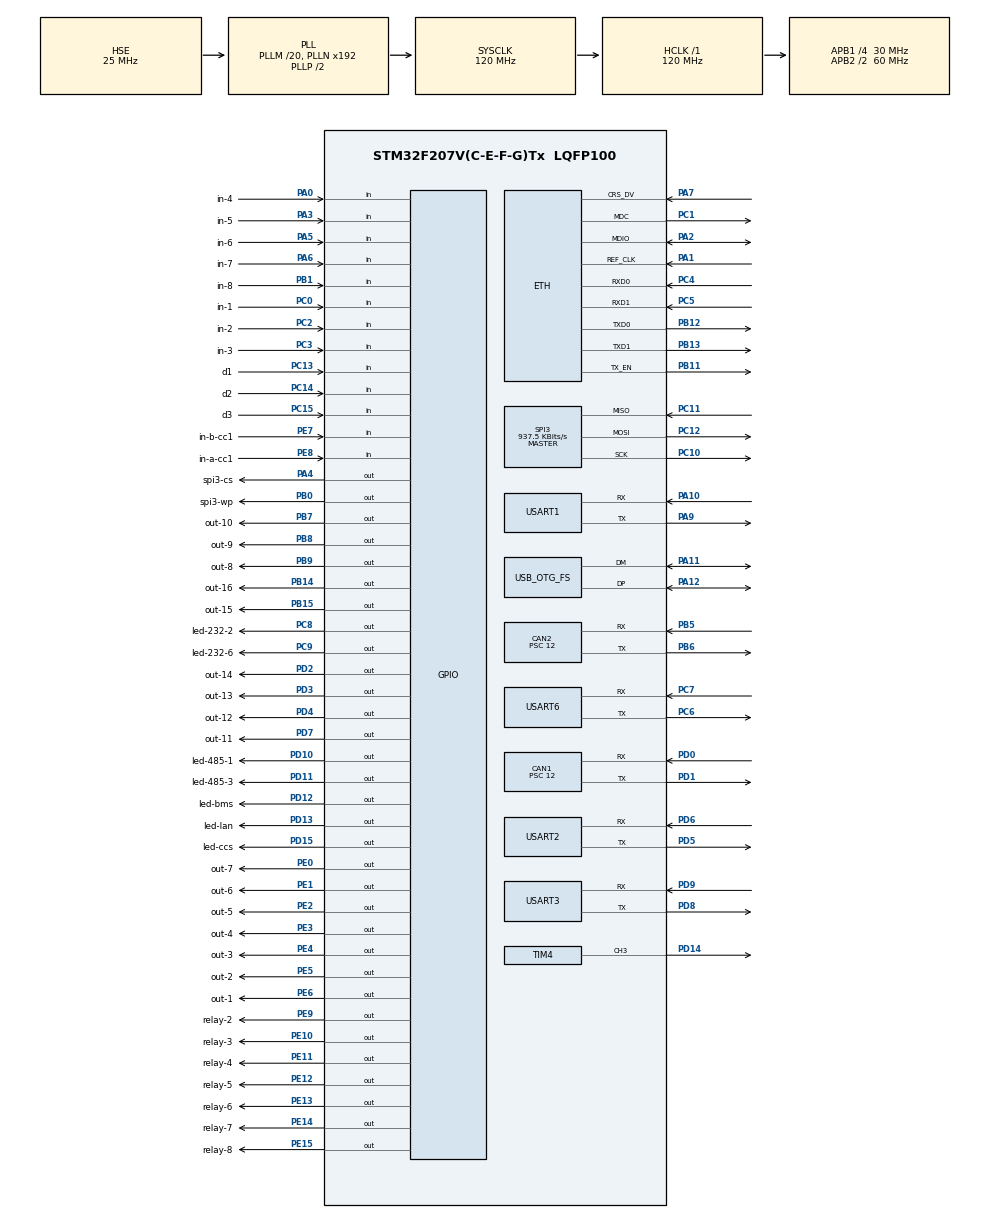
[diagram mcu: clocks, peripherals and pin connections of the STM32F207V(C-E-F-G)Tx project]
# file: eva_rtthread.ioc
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CAN1.ABOM=ENABLE
CAN1.AWUM=DISABLE
CAN1.BS1=CAN_BS1_3TQ
CAN1.BS2=CAN_BS2_6TQ
CAN1.CalculateTimeQuantum=400.0
CAN1.Mode=CAN_MODE_NORMAL
CAN1.NART=ENABLE
CAN1.Prescaler=12
CAN2.ABOM=ENABLE
CAN2.AWUM=DISABLE
CAN2.BS1=CAN_BS1_3TQ
CAN2.BS2=CAN_BS2_6TQ
CAN2.CalculateTimeQuantum=400.0
CAN2.Mode=CAN_MODE_NORMAL
CAN2.NART=ENABLE
CAN2.Prescaler=12
Dma.Request0=USART1_RX
Dma.Request1=USART1_TX
Dma.Request2=USART3_RX
Dma.Request3=USART3_TX
Dma.Request4=USART2_RX
Dma.Request5=USART2_TX
Dma.Request6=USART6_RX
Dma.Request7=USART6_TX
Dma.USART1_RX.0.Direction=DMA_PERIPH_TO_MEMORY
Dma.USART1_RX.0.FIFOMode=DMA_FIFOMODE_DISABLE
Dma.USART1_RX.0.Instance=DMA2_Stream2
Dma.USART1_RX.0.MemDataAlignment=DMA_MDATAALIGN_BYTE
Dma.USART1_RX.0.MemInc=DMA_MINC_ENABLE
Dma.USART1_RX.0.Mode=DMA_NORMAL
Dma.USART1_RX.0.PeriphDataAlignment=DMA_PDATAALIGN_BYTE
Dma.USART1_RX.0.PeriphInc=DMA_PINC_DISABLE
Dma.USART1_RX.0.Priority=DMA_PRIORITY_LOW
Dma.USART1_TX.1.Direction=DMA_MEMORY_TO_PERIPH
Dma.USART1_TX.1.FIFOMode=DMA_FIFOMODE_DISABLE
Dma.USART1_TX.1.Instance=DMA2_Stream7
Dma.USART1_TX.1.MemDataAlignment=DMA_MDATAALIGN_BYTE
Dma.USART1_TX.1.MemInc=DMA_MINC_ENABLE
Dma.USART1_TX.1.Mode=DMA_NORMAL
Dma.USART1_TX.1.PeriphDataAlignment=DMA_PDATAALIGN_BYTE
Dma.USART1_TX.1.PeriphInc=DMA_PINC_DISABLE
Dma.USART1_TX.1.Priority=DMA_PRIORITY_LOW
Dma.USART2_RX.4.Direction=DMA_PERIPH_TO_MEMORY
Dma.USART2_RX.4.FIFOMode=DMA_FIFOMODE_DISABLE
Dma.USART2_RX.4.Instance=DMA1_Stream5
Dma.USART2_RX.4.MemDataAlignment=DMA_MDATAALIGN_BYTE
Dma.USART2_RX.4.MemInc=DMA_MINC_ENABLE
Dma.USART2_RX.4.Mode=DMA_NORMAL
Dma.USART2_RX.4.PeriphDataAlignment=DMA_PDATAALIGN_BYTE
Dma.USART2_RX.4.PeriphInc=DMA_PINC_DISABLE
Dma.USART2_RX.4.Priority=DMA_PRIORITY_LOW
Dma.USART2_TX.5.Direction=DMA_MEMORY_TO_PERIPH
Dma.USART2_TX.5.FIFOMode=DMA_FIFOMODE_DISABLE
Dma.USART2_TX.5.Instance=DMA1_Stream6
Dma.USART2_TX.5.MemDataAlignment=DMA_MDATAALIGN_BYTE
Dma.USART2_TX.5.MemInc=DMA_MINC_ENABLE
Dma.USART2_TX.5.Mode=DMA_NORMAL
Dma.USART2_TX.5.PeriphDataAlignment=DMA_PDATAALIGN_BYTE
Dma.USART2_TX.5.PeriphInc=DMA_PINC_DISABLE
Dma.USART2_TX.5.Priority=DMA_PRIORITY_LOW
Dma.USART3_RX.2.Direction=DMA_PERIPH_TO_MEMORY
Dma.USART3_RX.2.FIFOMode=DMA_FIFOMODE_DISABLE
Dma.USART3_RX.2.Instance=DMA1_Stream1
Dma.USART3_RX.2.MemDataAlignment=DMA_MDATAALIGN_BYTE
Dma.USART3_RX.2.MemInc=DMA_MINC_ENABLE
Dma.USART3_RX.2.Mode=DMA_NORMAL
Dma.USART3_RX.2.PeriphDataAlignment=DMA_PDATAALIGN_BYTE
Dma.USART3_RX.2.PeriphInc=DMA_PINC_DISABLE
Dma.USART3_RX.2.Priority=DMA_PRIORITY_LOW
Dma.USART3_TX.3.Direction=DMA_MEMORY_TO_PERIPH
Dma.USART3_TX.3.FIFOMode=DMA_FIFOMODE_DISABLE
Dma.USART3_TX.3.Instance=DMA1_Stream3
Dma.USART3_TX.3.MemDataAlignment=DMA_MDATAALIGN_BYTE
Dma.USART3_TX.3.MemInc=DMA_MINC_ENABLE
Dma.USART3_TX.3.Mode=DMA_NORMAL
Dma.USART3_TX.3.PeriphDataAlignment=DMA_PDATAALIGN_BYTE
Dma.USART3_TX.3.PeriphInc=DMA_PINC_DISABLE
Dma.USART3_TX.3.Priority=DMA_PRIORITY_LOW
Dma.USART6_RX.6.Direction=DMA_PERIPH_TO_MEMORY
Dma.USART6_RX.6.FIFOMode=DMA_FIFOMODE_DISABLE
Dma.USART6_RX.6.Instance=DMA2_Stream1
Dma.USART6_RX.6.MemDataAlignment=DMA_MDATAALIGN_BYTE
Dma.USART6_RX.6.MemInc=DMA_MINC_ENABLE
Dma.USART6_RX.6.Mode=DMA_NORMAL
Dma.USART6_RX.6.PeriphDataAlignment=DMA_PDATAALIGN_BYTE
Dma.USART6_RX.6.PeriphInc=DMA_PINC_DISABLE
Dma.USART6_RX.6.Priority=DMA_PRIORITY_LOW
Dma.USART6_TX.7.Direction=DMA_MEMORY_TO_PERIPH
Dma.USART6_TX.7.FIFOMode=DMA_FIFOMODE_DISABLE
Dma.USART6_TX.7.Instance=DMA2_Stream6
Dma.USART6_TX.7.MemDataAlignment=DMA_MDATAALIGN_BYTE
Dma.USART6_TX.7.MemInc=DMA_MINC_ENABLE
Dma.USART6_TX.7.Mode=DMA_NORMAL
Dma.USART6_TX.7.PeriphDataAlignment=DMA_PDATAALIGN_BYTE
Dma.USART6_TX.7.PeriphInc=DMA_PINC_DISABLE
Dma.USART6_TX.7.Priority=DMA_PRIORITY_LOW
ETH.MediaInterface=ETH_MEDIA_INTERFACE_RMII
ETH.RxMode=ETH_RXINTERRUPT_MODE
IWDG.Prescaler=IWDG_PRESCALER_32
MBEDTLS.MBEDTLS_SSL_CLI_C=1
Mcu.Family=STM32F2
Mcu.Name=STM32F207V(C-E-F-G)Tx
Mcu.Package=LQFP100
NVIC.CAN1_RX0_IRQn=true\:0\:0\:false\:false\:true\:true\:true
NVIC.CAN1_TX_IRQn=true\:0\:0\:false\:false\:true\:true\:true
NVIC.CAN2_RX1_IRQn=true\:0\:0\:false\:false\:true\:true\:true
NVIC.CAN2_TX_IRQn=true\:0\:0\:false\:false\:true\:true\:true
NVIC.DMA1_Stream1_IRQn=true\:0\:0\:false\:false\:true\:false\:true
NVIC.DMA1_Stream3_IRQn=true\:0\:0\:false\:false\:true\:false\:true
NVIC.DMA1_Stream5_IRQn=true\:0\:0\:false\:false\:true\:false\:true
NVIC.DMA1_Stream6_IRQn=true\:0\:0\:false\:false\:true\:false\:true
NVIC.DMA2_Stream1_IRQn=true\:0\:0\:false\:false\:true\:false\:true
NVIC.DMA2_Stream2_IRQn=true\:0\:0\:false\:false\:true\:false\:true
NVIC.DMA2_Stream6_IRQn=true\:0\:0\:false\:false\:true\:false\:true
NVIC.DMA2_Stream7_IRQn=true\:0\:0\:false\:false\:true\:false\:true
NVIC.ETH_IRQn=true\:0\:0\:false\:false\:true\:true\:true
NVIC.OTG_FS_IRQn=true\:0\:0\:false\:false\:true\:false\:true
NVIC.PriorityGroup=NVIC_PRIORITYGROUP_4
NVIC.SPI3_IRQn=true\:0\:0\:false\:false\:true\:true\:true
NVIC.TIM1_UP_TIM10_IRQn=true\:0\:0\:false\:false\:true\:false\:true
NVIC.TimeBase=TIM1_UP_TIM10_IRQn
NVIC.TimeBaseIP=TIM1
NVIC.USART1_IRQn=true\:0\:0\:false\:false\:true\:true\:true
NVIC.USART2_IRQn=true\:0\:0\:false\:false\:true\:true\:true
NVIC.USART3_IRQn=true\:0\:0\:false\:false\:true\:true\:true
NVIC.USART6_IRQn=true\:0\:0\:false\:false\:true\:true\:true
PA0-WKUP.GPIO_Label=in-4
PA0-WKUP.Signal=GPIO_Input
PA1.Mode=RMII
PA1.Signal=ETH_REF_CLK
PA10.Mode=Asynchronous
PA10.Signal=USART1_RX
PA11.Mode=Host_Only
PA11.Signal=USB_OTG_FS_DM
PA12.Mode=Host_Only
PA12.Signal=USB_OTG_FS_DP
PA13.Mode=Serial_Wire
PA13.Signal=SYS_JTMS-SWDIO
PA14.Mode=Serial_Wire
PA14.Signal=SYS_JTCK-SWCLK
PA2.Mode=RMII
PA2.Signal=ETH_MDIO
PA3.GPIO_Label=in-5
PA3.Signal=GPIO_Input
PA4.GPIO_Label=spi3-cs
PA4.Signal=GPIO_Output
PA5.GPIO_Label=in-6
PA5.Signal=GPIO_Input
PA6.GPIO_Label=in-7
PA6.Signal=GPIO_Input
PA7.Mode=RMII
PA7.Signal=ETH_CRS_DV
PA9.Mode=Asynchronous
PA9.Signal=USART1_TX
PB0.GPIO_Label=spi3-wp
PB0.Signal=GPIO_Output
PB1.GPIO_Label=in-8
PB1.Signal=GPIO_Input
PB11.Mode=RMII
PB11.Signal=ETH_TX_EN
PB12.Mode=RMII
PB12.Signal=ETH_TXD0
PB13.Mode=RMII
PB13.Signal=ETH_TXD1
PB14.GPIO_Label=out-16
PB14.Signal=GPIO_Output
PB15.GPIO_Label=out-15
PB15.Signal=GPIO_Output
PB5.GPIO_Mode=GPIO_MODE_AF_PP
PB5.GPIO_PuPd=GPIO_NOPULL
PB5.GPIO_Speed=GPIO_SPEED_FREQ_VERY_HIGH
PB5.Mode=Slave
PB5.Signal=CAN2_RX
PB6.GPIO_Mode=GPIO_MODE_AF_PP
PB6.GPIO_PuPd=GPIO_NOPULL
PB6.GPIO_Speed=GPIO_SPEED_FREQ_VERY_HIGH
PB6.Mode=Slave
PB6.Signal=CAN2_TX
PB7.GPIO_Label=out-10
PB7.Signal=GPIO_Output
PB8.GPIO_Label=out-9
PB8.Signal=GPIO_Output
PB9.GPIO_Label=out-8
PB9.Signal=GPIO_Output
PC0.GPIO_Label=in-1
PC0.Signal=GPIO_Input
PC1.Mode=RMII
PC1.Signal=ETH_MDC
PC10.Mode=Full_Duplex_Master
PC10.Signal=SPI3_SCK
PC11.Mode=Full_Duplex_Master
PC11.Signal=SPI3_MISO
PC12.Mode=Full_Duplex_Master
PC12.Signal=SPI3_MOSI
PC13.GPIO_Label=d1
PC13.GPIO_PuPd=GPIO_PULLUP
PC13.Signal=GPIO_Input
PC14-OSC32_IN.GPIO_Label=d2
PC14-OSC32_IN.GPIO_PuPd=GPIO_PULLUP
PC14-OSC32_IN.Signal=GPIO_Input
PC15-OSC32_OUT.GPIO_Label=d3
PC15-OSC32_OUT.GPIO_PuPd=GPIO_PULLUP
PC15-OSC32_OUT.Signal=GPIO_Input
PC2.GPIO_Label=in-2
PC2.Signal=GPIO_Input
PC3.GPIO_Label=in-3
PC3.Signal=GPIO_Input
PC4.Mode=RMII
PC4.Signal=ETH_RXD0
PC5.Mode=RMII
PC5.Signal=ETH_RXD1
PC6.Mode=Asynchronous
PC6.Signal=USART6_TX
PC7.Mode=Asynchronous
PC7.Signal=USART6_RX
PC8.GPIO_Label=led-232-2
PC8.Signal=GPIO_Output
PC9.GPIO_Label=led-232-6
PC9.Signal=GPIO_Output
PD0.Mode=Master
PD0.Signal=CAN1_RX
PD1.Mode=Master
PD1.Signal=CAN1_TX
PD10.GPIO_Label=led-485-1
PD10.Signal=GPIO_Output
PD11.GPIO_Label=led-485-3
PD11.Signal=GPIO_Output
PD12.GPIO_Label=led-bms
PD12.Signal=GPIO_Output
PD13.GPIO_Label=led-lan
PD13.Signal=GPIO_Output
PD14.Signal=S_TIM4_CH3
PD15.GPIO_Label=led-ccs
PD15.Signal=GPIO_Output
PD2.GPIO_Label=out-14
PD2.Signal=GPIO_Output
PD3.GPIO_Label=out-13
PD3.Signal=GPIO_Output
PD4.GPIO_Label=out-12
PD4.Signal=GPIO_Output
PD5.Mode=Asynchronous
PD5.Signal=USART2_TX
PD6.Mode=Asynchronous
PD6.Signal=USART2_RX
PD7.GPIO_Label=out-11
PD7.Signal=GPIO_Output
PD8.Mode=Asynchronous
PD8.Signal=USART3_TX
PD9.Mode=Asynchronous
PD9.Signal=USART3_RX
PE0.GPIO_Label=out-7
PE0.Signal=GPIO_Output
PE1.GPIO_Label=out-6
PE1.Signal=GPIO_Output
PE10.GPIO_Label=relay-3
PE10.Signal=GPIO_Output
PE11.GPIO_Label=relay-4
PE11.Signal=GPIO_Output
PE12.GPIO_Label=relay-5
PE12.Signal=GPIO_Output
PE13.GPIO_Label=relay-6
PE13.Signal=GPIO_Output
PE14.GPIO_Label=relay-7
PE14.Signal=GPIO_Output
PE15.GPIO_Label=relay-8
PE15.Signal=GPIO_Output
PE2.GPIO_Label=out-5
PE2.Signal=GPIO_Output
PE3.GPIO_Label=out-4
PE3.Signal=GPIO_Output
PE4.GPIO_Label=out-3
PE4.Signal=GPIO_Output
PE5.GPIO_Label=out-2
PE5.Signal=GPIO_Output
PE6.GPIO_Label=out-1
PE6.Signal=GPIO_Output
PE7.GPIO_Label=in-b-cc1
PE7.Signal=GPIO_Input
PE8.GPIO_Label=in-a-cc1
PE8.Signal=GPIO_Input
PE9.GPIO_Label=relay-2
PE9.Signal=GPIO_Output
PH0-OSC_IN.Mode=HSE-External-Oscillator
PH0-OSC_IN.Signal=RCC_OSC_IN
PH1-OSC_OUT.Mode=HSE-External-Oscillator
PH1-OSC_OUT.Signal=RCC_OSC_OUT
ProjectManager.HeapSize=0x200
ProjectManager.StackSize=0x400
ProjectManager.TargetToolchain=Makefile
RCC.48MHZClocksFreq_Value=48000000
RCC.AHBFreq_Value=120000000
RCC.APB1CLKDivider=RCC_HCLK_DIV4
RCC.APB1Freq_Value=30000000
RCC.APB1TimFreq_Value=60000000
RCC.APB2CLKDivider=RCC_HCLK_DIV2
RCC.APB2Freq_Value=60000000
RCC.APB2TimFreq_Value=120000000
RCC.CortexFreq_Value=120000000
RCC.HCLKFreq_Value=120000000
RCC.HSE_VALUE=25000000
RCC.HSI_VALUE=16000000
RCC.LSE_VALUE=32768
RCC.PLLM=20
RCC.PLLQ=5
RCC.PLLSourceVirtual=RCC_PLLSOURCE_HSE
RCC.SYSCLKFreq_VALUE=120000000
RCC.SYSCLKSource=RCC_SYSCLKSOURCE_PLLCLK
RCC.VCOOutputFreq_Value=240000000
SH.S_TIM4_CH3.0=TIM4_CH3,PWM Generation3 CH3
SPI3.BaudRatePrescaler=SPI_BAUDRATEPRESCALER_32
SPI3.CalculateBaudRate=937.5 KBits/s
SPI3.Direction=SPI_DIRECTION_2LINES
SPI3.Mode=SPI_MODE_MASTER
SPI3.VirtualType=VM_MASTER
TIM4.Channel-PWM\ Generation3\ CH3=TIM_CHANNEL_3
TIM4.Period=1000 - 1
TIM4.Prescaler=60
USART1.VirtualMode=VM_ASYNC
USART2.VirtualMode=VM_ASYNC
USART3.VirtualMode=VM_ASYNC
USART6.VirtualMode=VM_ASYNC
USB_HOST.BSP.number=1
USB_HOST.USBH_HandleTypeDef-MSC_FS=hUsbHostFS
USB_HOST.USBH_USE_OS-MSC_FS=0
USB_HOST.VirtualModeFS=Msc
USB_HOST0.BSP.STBoard=false
USB_HOST0.BSP.api=Unknown
USB_HOST0.BSP.i2caddr=0
USB_HOST0.BSP.instance=PE15
USB_HOST0.BSP.ip=GPIO
USB_HOST0.BSP.mode=Output
USB_HOST0.BSP.name=Drive_VBUS_FS
USB_HOST0.BSP.solution=PE15
USB_OTG_FS.VirtualMode=Host_Only
USB_OTG_FS.phy_itface=HCD_PHY_EMBEDDED
VP_IWDG_VS_IWDG.Mode=IWDG_Activate
VP_MBEDTLS_VS_MBEDTLS.Mode=Enabled
VP_RNG_VS_RNG.Mode=RNG_Activate
VP_SYS_VS_tim1.Mode=TIM1
VP_USB_HOST_VS_USB_HOST_MSC_FS.Mode=MSC_FS
board=custom

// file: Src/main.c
/* USER CODE BEGIN Header */
/**
  ******************************************************************************
  * @file           : main.c
  * @brief          : Main program body
  ******************************************************************************
  * @attention
  *
  * <h2><center>&copy; Copyright (c) 2020 STMicroelectronics.
  * All rights reserved.</center></h2>
  *
  * This software component is licensed by ST under Ultimate Liberty license
  * SLA0044, the "License"; You may not use this file except in compliance with
  * the License. You may obtain a copy of the License at:
  *                             www.st.com/SLA0044
  *
  ******************************************************************************
  */
/* USER CODE END Header */

#include "main.h"
#include "can.h"
#include "dma.h"
#include "eth.h"
#include "iwdg.h"
#include "mbedtls.h"
#include "rng.h"
#include "spi.h"
#include "tim.h"
#include "usart.h"
#include "usb_host.h"
#include "gpio.h"

/* USER CODE BEGIN Includes */

#include "startup.h"

/* USER CODE END Includes */

void SystemClock_Config(void);
void MX_USB_HOST_Process(void);

int main(void)
{

  /* MCU Configuration--------------------------------------------------------*/

  /* Reset of all peripherals, Initializes the Flash interface and the Systick. */
  HAL_Init();

  /* Configure the system clock */
  SystemClock_Config();

  /* Initialize all configured peripherals */
  MX_GPIO_Init();
  MX_DMA_Init();
  MX_CAN1_Init();
  MX_CAN2_Init();
  MX_USART1_UART_Init();
  MX_USART3_UART_Init();
  MX_USB_HOST_Init();
  MX_TIM4_Init();
  MX_SPI3_Init();
  MX_USART2_UART_Init();
  MX_USART6_UART_Init();
  MX_MBEDTLS_Init();
  MX_ETH_Init();
  MX_RNG_Init();
  /* USER CODE BEGIN 2 */

  rtthread_startup();

  /* USER CODE END 2 */

  /* Infinite loop */
  while (1)
  {
    MX_USB_HOST_Process();

  }
}

void SystemClock_Config(void)
{
  RCC_OscInitTypeDef RCC_OscInitStruct = {0};
  RCC_ClkInitTypeDef RCC_ClkInitStruct = {0};

  /** Initializes the CPU, AHB and APB busses clocks
  */
  RCC_OscInitStruct.OscillatorType = RCC_OSCILLATORTYPE_LSI|RCC_OSCILLATORTYPE_HSE;
  RCC_OscInitStruct.HSEState = RCC_HSE_ON;
  RCC_OscInitStruct.LSIState = RCC_LSI_ON;
  RCC_OscInitStruct.PLL.PLLState = RCC_PLL_ON;
  RCC_OscInitStruct.PLL.PLLSource = RCC_PLLSOURCE_HSE;
  RCC_OscInitStruct.PLL.PLLM = 20;
  RCC_OscInitStruct.PLL.PLLN = 192;
  RCC_OscInitStruct.PLL.PLLP = RCC_PLLP_DIV2;
  RCC_OscInitStruct.PLL.PLLQ = 5;
  if (HAL_RCC_OscConfig(&RCC_OscInitStruct) != HAL_OK)
  {
    Error_Handler();
  }
  /** Initializes the CPU, AHB and APB busses clocks
  */
  RCC_ClkInitStruct.ClockType = RCC_CLOCKTYPE_HCLK|RCC_CLOCKTYPE_SYSCLK
                              |RCC_CLOCKTYPE_PCLK1|RCC_CLOCKTYPE_PCLK2;
  RCC_ClkInitStruct.SYSCLKSource = RCC_SYSCLKSOURCE_PLLCLK;
  RCC_ClkInitStruct.AHBCLKDivider = RCC_SYSCLK_DIV1;
  RCC_ClkInitStruct.APB1CLKDivider = RCC_HCLK_DIV4;
  RCC_ClkInitStruct.APB2CLKDivider = RCC_HCLK_DIV2;

  if (HAL_RCC_ClockConfig(&RCC_ClkInitStruct, FLASH_LATENCY_3) != HAL_OK)
  {
    Error_Handler();
  }
}

 /**
  * @brief  Period elapsed callback in non blocking mode
  * @note   This function is called  when TIM1 interrupt took place, inside
  * HAL_TIM_IRQHandler(). It makes a direct call to HAL_IncTick() to increment
  * a global variable "uwTick" used as application time base.
  * @param  htim : TIM handle
  * @retval None
  */
__weak void HAL_TIM_PeriodElapsedCallback(TIM_HandleTypeDef *htim)
{
  if (htim->Instance == TIM1) {
    HAL_IncTick();
  }
}

void Error_Handler(void)
{
}

/************************ (C) COPYRIGHT STMicroelectronics *****END OF FILE****/
